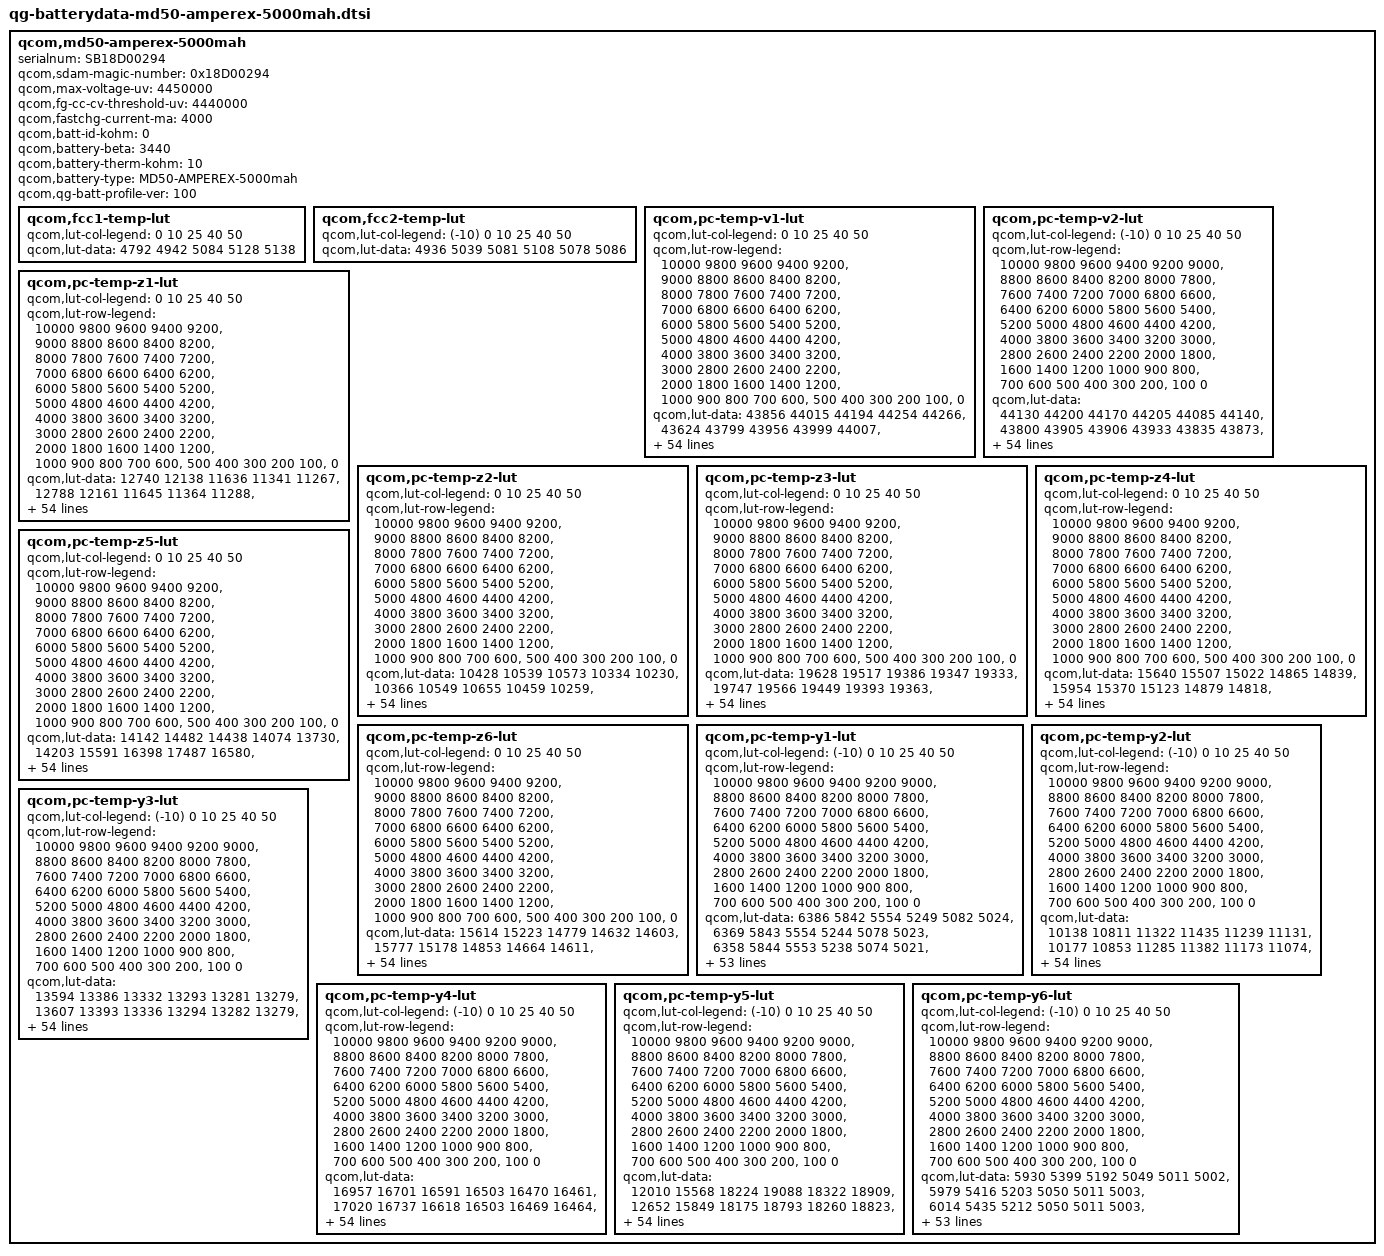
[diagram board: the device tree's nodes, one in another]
qcom,md50-amperex-5000mah {
    /* 4951798_Lenovo_Denver_5000mAH_PM7250B_averaged_MasterSlave_Dec1th2020 */
    serialnum = "SB18D00294";
    qcom,sdam-magic-number = <0x18D00294>;
    qcom,max-voltage-uv = <4450000>;
    qcom,fg-cc-cv-threshold-uv = <4440000>;
    qcom,fastchg-current-ma = <4000>;
    qcom,batt-id-kohm = <0>;
    qcom,battery-beta = <3440>;
    qcom,battery-therm-kohm = <10>;
    qcom,battery-type = "MD50-AMPEREX-5000mah";
    qcom,qg-batt-profile-ver = <100>;

	qcom,fcc1-temp-lut {
		qcom,lut-col-legend = <0 10 25 40 50>;
		qcom,lut-data = <4792 4942 5084 5128 5138>;
	};

	qcom,fcc2-temp-lut {
		qcom,lut-col-legend = <(-10) 0 10 25 40 50>;
		qcom,lut-data = <4936 5039 5081 5108 5078 5086>;
	};

	qcom,pc-temp-v1-lut {
		qcom,lut-col-legend = <0 10 25 40 50>;
		qcom,lut-row-legend = <10000 9800 9600 9400 9200>,
			<9000 8800 8600 8400 8200>,
			<8000 7800 7600 7400 7200>,
			<7000 6800 6600 6400 6200>,
			<6000 5800 5600 5400 5200>,
			<5000 4800 4600 4400 4200>,
			<4000 3800 3600 3400 3200>,
			<3000 2800 2600 2400 2200>,
			<2000 1800 1600 1400 1200>,
			<1000 900 800 700 600>,
			<500 400 300 200 100>,
			<0>;
		qcom,lut-data = <43856 44015 44194 44254 44266>,
			<43624 43799 43956 43999 44007>,
			<43397 43578 43741 43782 43786>,
			<43170 43352 43528 43574 43581>,
			<42935 43121 43301 43357 43368>,
			<42695 42884 43063 43127 43141>,
			<42459 42639 42824 42891 42908>,
			<42222 42398 42582 42652 42671>,
			<41990 42168 42338 42407 42430>,
			<41766 41944 42097 42165 42189>,
			<41548 41715 41857 41925 41950>,
			<41334 41479 41622 41687 41712>,
			<41123 41252 41393 41455 41480>,
			<40918 41040 41169 41226 41250>,
			<40714 40837 40952 41007 41028>,
			<40511 40638 40742 40796 40812>,
			<40318 40439 40542 40593 40604>,
			<40142 40250 40350 40396 40406>,
			<39977 40081 40167 40208 40216>,
			<39820 39922 40005 40034 40042>,
			<39676 39751 39845 39873 39884>,
			<39530 39563 39629 39678 39696>,
			<39363 39363 39322 39391 39416>,
			<39176 39133 39073 39122 39145>,
			<38999 38886 38935 38971 38992>,
			<38828 38733 38830 38862 38883>,
			<38676 38653 38734 38760 38781>,
			<38580 38591 38649 38663 38682>,
			<38517 38526 38570 38573 38587>,
			<38465 38464 38494 38487 38489>,
			<38417 38406 38425 38407 38395>,
			<38374 38351 38360 38331 38313>,
			<38335 38300 38301 38258 38242>,
			<38300 38254 38244 38191 38175>,
			<38268 38212 38191 38129 38107>,
			<38234 38171 38140 38070 38041>,
			<38202 38135 38091 38014 37975>,
			<38161 38095 38045 37961 37913>,
			<38101 38033 37983 37894 37837>,
			<38021 37940 37893 37798 37734>,
			<37926 37834 37786 37685 37616>,
			<37804 37715 37671 37573 37499>,
			<37664 37576 37540 37451 37372>,
			<37501 37407 37373 37291 37210>,
			<37350 37250 37218 37144 37068>,
			<37242 37150 37112 37049 36989>,
			<37197 37116 37078 37019 36957>,
			<37159 37095 37059 36998 36937>,
			<37128 37073 37036 36979 36915>,
			<37093 37032 36997 36932 36857>,
			<37022 36852 36798 36704 36606>,
			<36747 36412 36372 36271 36168>,
			<36244 35823 35797 35695 35590>,
			<35563 34994 35011 34912 34804>,
			<34404 33567 33789 33692 33577>,
			<30000 30000 30000 30000 30000>;
	};

	qcom,pc-temp-v2-lut {
		qcom,lut-col-legend = <(-10) 0 10 25 40 50>;
		qcom,lut-row-legend = <10000 9800 9600 9400 9200 9000>,
			<8800 8600 8400 8200 8000 7800>,
			<7600 7400 7200 7000 6800 6600>,
			<6400 6200 6000 5800 5600 5400>,
			<5200 5000 4800 4600 4400 4200>,
			<4000 3800 3600 3400 3200 3000>,
			<2800 2600 2400 2200 2000 1800>,
			<1600 1400 1200 1000 900 800>,
			<700 600 500 400 300 200>,
			<100 0>;
		qcom,lut-data = <44130 44200 44170 44205 44085 44140>,
			<43800 43905 43906 43933 43835 43873>,
			<43497 43631 43652 43674 43592 43618>,
			<43228 43380 43411 43433 43359 43381>,
			<42993 43154 43183 43210 43135 43160>,
			<42759 42925 42952 42981 42908 42935>,
			<42498 42680 42709 42741 42670 42699>,
			<42232 42430 42462 42497 42428 42458>,
			<41997 42182 42216 42253 42187 42217>,
			<41792 41935 41969 42008 41946 41975>,
			<41589 41695 41727 41767 41709 41738>,
			<41370 41463 41490 41528 41475 41503>,
			<41142 41240 41259 41296 41246 41273>,
			<40906 41036 41036 41071 41023 41048>,
			<40663 40849 40821 40851 40805 40829>,
			<40407 40644 40614 40640 40597 40619>,
			<40119 40400 40420 40433 40394 40417>,
			<39810 40142 40224 40234 40201 40223>,
			<39538 39892 40010 40052 40021 40041>,
			<39306 39644 39782 39874 39850 39867>,
			<39092 39412 39550 39669 39656 39675>,
			<38885 39197 39305 39425 39421 39455>,
			<38690 38999 39079 39192 39190 39237>,
			<38531 38821 38897 38991 38994 39034>,
			<38400 38661 38737 38811 38817 38843>,
			<38293 38510 38596 38665 38672 38692>,
			<38215 38360 38472 38543 38553 38571>,
			<38154 38227 38358 38435 38448 38464>,
			<38098 38125 38250 38334 38352 38363>,
			<38045 38040 38149 38241 38263 38269>,
			<37994 37978 38056 38156 38182 38186>,
			<37941 37933 37968 38077 38107 38110>,
			<37887 37894 37898 38006 38035 38037>,
			<37830 37848 37848 37943 37968 37970>,
			<37771 37801 37807 37882 37902 37901>,
			<37711 37751 37767 37816 37821 37810>,
			<37647 37700 37728 37746 37726 37696>,
			<37583 37644 37683 37672 37630 37587>,
			<37512 37578 37624 37594 37537 37492>,
			<37432 37500 37552 37512 37444 37401>,
			<37346 37411 37458 37426 37356 37310>,
			<37253 37302 37336 37330 37268 37217>,
			<37151 37177 37200 37207 37146 37100>,
			<37056 37032 37041 37068 37006 36963>,
			<36968 36873 36868 36935 36894 36839>,
			<36886 36755 36766 36882 36854 36801>,
			<36849 36715 36735 36865 36841 36790>,
			<36804 36681 36697 36844 36827 36776>,
			<36761 36645 36644 36815 36802 36748>,
			<36715 36592 36550 36745 36708 36645>,
			<36655 36493 36314 36489 36403 36324>,
			<36545 36197 35854 35990 35885 35813>,
			<36308 35588 35195 35337 35218 35144>,
			<35798 34615 34216 34436 34271 34212>,
			<34977 33356 32765 33077 33015 32896>,
			<34023 31708 27243 28003 28075 28051>;
	};

	qcom,pc-temp-z1-lut {
		qcom,lut-col-legend = <0 10 25 40 50>;
		qcom,lut-row-legend = <10000 9800 9600 9400 9200>,
			<9000 8800 8600 8400 8200>,
			<8000 7800 7600 7400 7200>,
			<7000 6800 6600 6400 6200>,
			<6000 5800 5600 5400 5200>,
			<5000 4800 4600 4400 4200>,
			<4000 3800 3600 3400 3200>,
			<3000 2800 2600 2400 2200>,
			<2000 1800 1600 1400 1200>,
			<1000 900 800 700 600>,
			<500 400 300 200 100>,
			<0>;
		qcom,lut-data = <12740 12138 11636 11341 11267>,
			<12788 12161 11645 11364 11288>,
			<12778 12168 11641 11362 11288>,
			<12768 12159 11636 11361 11289>,
			<12759 12139 11628 11359 11289>,
			<12739 12120 11615 11355 11288>,
			<12727 12099 11603 11351 11287>,
			<12713 12084 11593 11348 11287>,
			<12699 12078 11584 11347 11288>,
			<12686 12074 11576 11347 11290>,
			<12675 12066 11569 11349 11295>,
			<12661 12049 11567 11351 11299>,
			<12642 12036 11570 11351 11300>,
			<12620 12031 11572 11351 11300>,
			<12605 12028 11572 11351 11300>,
			<12590 12028 11571 11352 11301>,
			<12580 12028 11570 11353 11302>,
			<12576 12029 11572 11354 11304>,
			<12574 12027 11574 11355 11306>,
			<12573 12025 11576 11357 11307>,
			<12568 12025 11578 11359 11309>,
			<12563 12037 11579 11361 11311>,
			<12564 12049 11580 11361 11312>,
			<12569 12048 11580 11362 11313>,
			<12572 12044 11582 11363 11315>,
			<12568 12042 11586 11366 11317>,
			<12564 12045 11590 11369 11319>,
			<12569 12050 11595 11372 11322>,
			<12597 12058 11600 11376 11325>,
			<12620 12072 11605 11379 11329>,
			<12624 12077 11609 11383 11332>,
			<12622 12075 11614 11388 11336>,
			<12622 12073 11617 11392 11340>,
			<12624 12075 11622 11397 11343>,
			<12627 12083 11628 11402 11348>,
			<12630 12091 11635 11407 11353>,
			<12640 12099 11641 11412 11357>,
			<12651 12107 11647 11416 11361>,
			<12663 12121 11654 11420 11364>,
			<12678 12143 11661 11425 11367>,
			<12699 12156 11668 11429 11370>,
			<12734 12158 11677 11434 11374>,
			<12752 12161 11688 11439 11377>,
			<12758 12183 11700 11444 11380>,
			<12779 12197 11716 11451 11384>,
			<12813 12205 11726 11456 11387>,
			<12816 12195 11726 11457 11387>,
			<12789 12200 11726 11457 11387>,
			<12767 12199 11732 11459 11390>,
			<12770 12202 11731 11464 11394>,
			<12816 12213 11739 11470 11397>,
			<12807 12226 11759 11478 11404>,
			<12842 12245 11775 11488 11413>,
			<12897 12294 11789 11503 11427>,
			<12897 12294 11789 11503 11427>,
			<12897 12294 11789 11503 11427>;
	};

	qcom,pc-temp-z2-lut {
		qcom,lut-col-legend = <0 10 25 40 50>;
		qcom,lut-row-legend = <10000 9800 9600 9400 9200>,
			<9000 8800 8600 8400 8200>,
			<8000 7800 7600 7400 7200>,
			<7000 6800 6600 6400 6200>,
			<6000 5800 5600 5400 5200>,
			<5000 4800 4600 4400 4200>,
			<4000 3800 3600 3400 3200>,
			<3000 2800 2600 2400 2200>,
			<2000 1800 1600 1400 1200>,
			<1000 900 800 700 600>,
			<500 400 300 200 100>,
			<0>;
		qcom,lut-data = <10428 10539 10573 10334 10230>,
			<10366 10549 10655 10459 10259>,
			<10342 10545 10631 10553 10453>,
			<10323 10514 10591 10522 10435>,
			<10302 10464 10552 10487 10415>,
			<10285 10427 10507 10442 10394>,
			<10273 10394 10470 10401 10370>,
			<10264 10375 10441 10378 10333>,
			<10258 10407 10418 10361 10287>,
			<10269 10467 10397 10341 10274>,
			<10309 10473 10380 10313 10277>,
			<10329 10414 10375 10298 10281>,
			<10304 10372 10386 10317 10283>,
			<10272 10384 10401 10349 10285>,
			<10270 10409 10418 10352 10291>,
			<10278 10437 10438 10342 10310>,
			<10291 10473 10461 10337 10327>,
			<10315 10507 10491 10348 10333>,
			<10353 10533 10515 10367 10337>,
			<10391 10555 10525 10378 10326>,
			<10429 10573 10534 10385 10279>,
			<10463 10587 10570 10406 10263>,
			<10486 10599 10700 10577 10473>,
			<10503 10612 10781 10744 10706>,
			<10516 10624 10697 10640 10634>,
			<10527 10626 10574 10372 10396>,
			<10536 10614 10558 10293 10315>,
			<10543 10602 10576 10329 10337>,
			<10547 10605 10597 10372 10377>,
			<10551 10620 10626 10405 10506>,
			<10558 10633 10652 10443 10701>,
			<10566 10646 10660 10476 10731>,
			<10575 10655 10664 10541 10623>,
			<10586 10656 10665 10577 10498>,
			<10597 10656 10664 10555 10379>,
			<10607 10656 10663 10526 10281>,
			<10617 10661 10665 10525 10273>,
			<10629 10670 10669 10540 10299>,
			<10646 10685 10678 10565 10334>,
			<10668 10710 10717 10642 10393>,
			<10694 10733 10757 10714 10458>,
			<10724 10748 10771 10705 10497>,
			<10770 10768 10780 10671 10531>,
			<10855 10816 10790 10663 10597>,
			<11173 11075 10863 10645 10585>,
			<10956 11260 10953 10559 10451>,
			<10881 11255 10928 10553 10429>,
			<10872 11442 10907 10553 10460>,
			<10766 11821 10906 10568 10475>,
			<10663 11979 10974 10653 10540>,
			<10630 11837 11025 10606 10480>,
			<10549 11596 10970 10403 10240>,
			<10360 11358 10868 10315 10161>,
			<10190 10935 10774 10279 10120>,
			<10190 10935 10774 10279 10120>,
			<10190 10935 10774 10279 10120>;
	};

	qcom,pc-temp-z3-lut {
		qcom,lut-col-legend = <0 10 25 40 50>;
		qcom,lut-row-legend = <10000 9800 9600 9400 9200>,
			<9000 8800 8600 8400 8200>,
			<8000 7800 7600 7400 7200>,
			<7000 6800 6600 6400 6200>,
			<6000 5800 5600 5400 5200>,
			<5000 4800 4600 4400 4200>,
			<4000 3800 3600 3400 3200>,
			<3000 2800 2600 2400 2200>,
			<2000 1800 1600 1400 1200>,
			<1000 900 800 700 600>,
			<500 400 300 200 100>,
			<0>;
		qcom,lut-data = <19628 19517 19386 19347 19333>,
			<19747 19566 19449 19393 19363>,
			<19786 19594 19460 19413 19395>,
			<19802 19604 19466 19418 19399>,
			<19806 19610 19475 19422 19404>,
			<19809 19611 19485 19429 19413>,
			<19809 19610 19488 19433 19419>,
			<19806 19610 19484 19434 19420>,
			<19802 19616 19479 19435 19419>,
			<19799 19624 19476 19435 19418>,
			<19796 19620 19473 19432 19414>,
			<19793 19594 19469 19428 19411>,
			<19781 19571 19461 19424 19407>,
			<19765 19563 19454 19419 19404>,
			<19758 19557 19449 19413 19401>,
			<19755 19550 19445 19406 19397>,
			<19752 19539 19442 19399 19393>,
			<19739 19531 19438 19395 19389>,
			<19718 19529 19433 19391 19384>,
			<19705 19528 19425 19386 19377>,
			<19699 19529 19417 19379 19367>,
			<19695 19535 19419 19377 19363>,
			<19697 19543 19441 19387 19370>,
			<19707 19549 19455 19398 19378>,
			<19712 19554 19443 19389 19371>,
			<19712 19555 19424 19367 19349>,
			<19711 19546 19417 19357 19339>,
			<19709 19536 19413 19355 19337>,
			<19702 19531 19412 19354 19337>,
			<19693 19528 19415 19356 19352>,
			<19687 19527 19419 19361 19383>,
			<19682 19530 19424 19369 19390>,
			<19676 19532 19429 19384 19387>,
			<19670 19533 19433 19393 19384>,
			<19665 19533 19434 19392 19378>,
			<19660 19533 19435 19390 19371>,
			<19656 19530 19433 19386 19365>,
			<19652 19525 19426 19378 19359>,
			<19647 19522 19421 19374 19356>,
			<19641 19518 19419 19374 19354>,
			<19632 19513 19417 19374 19353>,
			<19619 19506 19412 19372 19355>,
			<19602 19497 19406 19369 19360>,
			<19580 19486 19402 19369 19367>,
			<19435 19451 19391 19366 19367>,
			<19315 19416 19376 19353 19346>,
			<19307 19412 19376 19347 19341>,
			<19304 19360 19369 19345 19333>,
			<19295 19299 19369 19337 19328>,
			<19294 19291 19356 19330 19324>,
			<19293 19295 19358 19341 19338>,
			<19297 19300 19358 19365 19362>,
			<19301 19301 19354 19367 19364>,
			<19323 19331 19348 19360 19359>,
			<19323 19331 19348 19360 19359>,
			<19323 19331 19348 19360 19359>;
	};

	qcom,pc-temp-z4-lut {
		qcom,lut-col-legend = <0 10 25 40 50>;
		qcom,lut-row-legend = <10000 9800 9600 9400 9200>,
			<9000 8800 8600 8400 8200>,
			<8000 7800 7600 7400 7200>,
			<7000 6800 6600 6400 6200>,
			<6000 5800 5600 5400 5200>,
			<5000 4800 4600 4400 4200>,
			<4000 3800 3600 3400 3200>,
			<3000 2800 2600 2400 2200>,
			<2000 1800 1600 1400 1200>,
			<1000 900 800 700 600>,
			<500 400 300 200 100>,
			<0>;
		qcom,lut-data = <15640 15507 15022 14865 14839>,
			<15954 15370 15123 14879 14818>,
			<15744 15252 15065 14906 14861>,
			<15522 15150 14978 14866 14835>,
			<15389 15063 14922 14833 14810>,
			<15277 14996 14878 14808 14789>,
			<15187 14945 14843 14786 14770>,
			<15113 14899 14817 14767 14754>,
			<15050 14842 14795 14749 14741>,
			<14990 14788 14775 14734 14727>,
			<14934 14772 14757 14719 14713>,
			<14897 14780 14742 14708 14701>,
			<14877 14785 14729 14700 14696>,
			<14862 14772 14719 14694 14692>,
			<14846 14755 14712 14691 14688>,
			<14827 14747 14706 14688 14685>,
			<14813 14744 14701 14686 14681>,
			<14806 14741 14696 14681 14678>,
			<14801 14731 14693 14677 14676>,
			<14792 14716 14691 14674 14673>,
			<14767 14712 14690 14672 14670>,
			<14745 14716 14697 14673 14671>,
			<14745 14725 14745 14718 14715>,
			<14754 14753 14787 14771 14771>,
			<14766 14804 14805 14792 14789>,
			<14791 14822 14817 14806 14800>,
			<14819 14817 14817 14808 14803>,
			<14825 14810 14809 14801 14795>,
			<14820 14801 14798 14789 14782>,
			<14813 14791 14785 14776 14754>,
			<14805 14779 14770 14759 14714>,
			<14795 14766 14754 14739 14693>,
			<14785 14753 14736 14712 14683>,
			<14774 14743 14722 14694 14677>,
			<14764 14734 14711 14685 14674>,
			<14753 14726 14703 14680 14673>,
			<14742 14719 14701 14679 14672>,
			<14733 14714 14700 14678 14671>,
			<14724 14712 14700 14678 14671>,
			<14716 14712 14705 14686 14682>,
			<14711 14711 14709 14695 14694>,
			<14707 14704 14707 14695 14691>,
			<14701 14696 14701 14691 14681>,
			<14689 14689 14696 14689 14679>,
			<14753 14670 14682 14680 14672>,
			<14856 14667 14662 14665 14661>,
			<14863 14666 14657 14664 14661>,
			<14863 14717 14650 14656 14656>,
			<14867 14779 14636 14644 14640>,
			<14865 14781 14643 14638 14631>,
			<14859 14781 14655 14654 14651>,
			<14860 14789 14671 14651 14651>,
			<14877 14795 14679 14655 14655>,
			<14876 14775 14689 14666 14663>,
			<14876 14775 14689 14666 14663>,
			<14876 14775 14689 14666 14663>;
	};

	qcom,pc-temp-z5-lut {
		qcom,lut-col-legend = <0 10 25 40 50>;
		qcom,lut-row-legend = <10000 9800 9600 9400 9200>,
			<9000 8800 8600 8400 8200>,
			<8000 7800 7600 7400 7200>,
			<7000 6800 6600 6400 6200>,
			<6000 5800 5600 5400 5200>,
			<5000 4800 4600 4400 4200>,
			<4000 3800 3600 3400 3200>,
			<3000 2800 2600 2400 2200>,
			<2000 1800 1600 1400 1200>,
			<1000 900 800 700 600>,
			<500 400 300 200 100>,
			<0>;
		qcom,lut-data = <14142 14482 14438 14074 13730>,
			<14203 15591 16398 17487 16580>,
			<14677 16416 16880 18337 19043>,
			<15195 16914 17289 18778 19541>,
			<15595 17313 17988 19329 20189>,
			<15992 17842 18934 20100 21526>,
			<16448 18519 19527 20931 22885>,
			<16998 19208 19762 21723 23631>,
			<17622 20065 19983 22520 24156>,
			<18330 20952 20431 23352 24885>,
			<19139 21255 21107 24237 26051>,
			<19912 21270 21788 25153 27250>,
			<20538 21388 22508 26334 28188>,
			<21192 22055 23293 27402 29049>,
			<22312 23124 24143 27480 29966>,
			<24428 23849 25071 27043 31021>,
			<25824 24265 26082 26808 32071>,
			<25632 24776 27403 27789 33357>,
			<25184 25829 28168 29056 34447>,
			<25160 27704 27921 29261 34010>,
			<27598 30682 27475 29278 31797>,
			<32007 37675 30444 29670 30838>,
			<39676 44278 48133 36586 34522>,
			<53017 46972 59546 43491 38576>,
			<59794 48773 48851 38538 34762>,
			<59547 48844 31968 25367 23362>,
			<58949 42032 26419 19929 18234>,
			<57523 34374 24057 18570 17023>,
			<52378 32068 23274 18011 16500>,
			<47310 30756 23490 18140 18989>,
			<44987 30436 23987 18552 24397>,
			<43313 31810 25044 19705 27123>,
			<42202 34038 27467 23751 28515>,
			<41307 36302 30347 27845 29266>,
			<40748 38982 34686 31221 29600>,
			<40849 40742 38088 33747 29822>,
			<41561 41758 38279 33841 29919>,
			<42531 42373 38149 33103 30051>,
			<44569 42424 37911 32761 30100>,
			<46946 42369 37090 32990 29657>,
			<46920 42232 35718 33239 28909>,
			<43256 39589 32660 30866 28053>,
			<41591 36883 29293 25971 27204>,
			<41383 35898 29387 27012 30897>,
			<27291 36795 30120 27861 33429>,
			<13418 29466 30007 25135 24159>,
			<13080 27846 30372 22553 21460>,
			<12951 19629 28007 22984 20085>,
			<12646 13094 31452 23001 21815>,
			<12597 12869 25755 22617 23443>,
			<12643 13066 23585 23372 25064>,
			<12749 13047 19601 24762 25585>,
			<12575 12882 17795 22685 23029>,
			<13336 14055 16375 18289 18472>,
			<13336 14055 16375 18289 18472>,
			<13336 14055 16375 18289 18472>;
	};

	qcom,pc-temp-z6-lut {
		qcom,lut-col-legend = <0 10 25 40 50>;
		qcom,lut-row-legend = <10000 9800 9600 9400 9200>,
			<9000 8800 8600 8400 8200>,
			<8000 7800 7600 7400 7200>,
			<7000 6800 6600 6400 6200>,
			<6000 5800 5600 5400 5200>,
			<5000 4800 4600 4400 4200>,
			<4000 3800 3600 3400 3200>,
			<3000 2800 2600 2400 2200>,
			<2000 1800 1600 1400 1200>,
			<1000 900 800 700 600>,
			<500 400 300 200 100>,
			<0>;
		qcom,lut-data = <15614 15223 14779 14632 14603>,
			<15777 15178 14853 14664 14611>,
			<15683 15132 14831 14685 14645>,
			<15579 15085 14796 14672 14638>,
			<15508 15039 14775 14661 14631>,
			<15444 15003 14758 14653 14627>,
			<15390 14973 14743 14646 14622>,
			<15344 14946 14728 14639 14617>,
			<15304 14920 14714 14632 14612>,
			<15268 14896 14702 14625 14606>,
			<15237 14879 14692 14618 14599>,
			<15210 14866 14683 14612 14593>,
			<15188 14855 14673 14606 14588>,
			<15168 14843 14665 14600 14585>,
			<15152 14831 14659 14595 14581>,
			<15138 14822 14654 14590 14577>,
			<15124 14814 14649 14585 14573>,
			<15109 14808 14645 14581 14569>,
			<15094 14801 14641 14577 14565>,
			<15079 14796 14636 14572 14560>,
			<15063 14795 14632 14567 14554>,
			<15051 14800 14637 14567 14552>,
			<15053 14809 14671 14594 14577>,
			<15062 14826 14693 14622 14604>,
			<15073 14852 14693 14622 14605>,
			<15086 14860 14691 14619 14601>,
			<15098 14855 14689 14616 14596>,
			<15099 14848 14684 14612 14592>,
			<15095 14842 14680 14608 14588>,
			<15089 14837 14676 14604 14585>,
			<15084 14833 14673 14600 14584>,
			<15078 14830 14669 14596 14581>,
			<15072 14827 14666 14593 14576>,
			<15066 14824 14663 14590 14571>,
			<15061 14822 14660 14588 14567>,
			<15057 14820 14658 14585 14564>,
			<15054 14817 14655 14582 14560>,
			<15052 14815 14653 14578 14557>,
			<15054 14816 14652 14576 14556>,
			<15056 14818 14654 14580 14559>,
			<15058 14819 14656 14584 14563>,
			<15060 14818 14655 14583 14563>,
			<15060 14815 14651 14580 14562>,
			<15057 14812 14650 14580 14565>,
			<15024 14795 14642 14576 14563>,
			<15014 14780 14628 14563 14547>,
			<15013 14777 14626 14560 14545>,
			<15012 14773 14620 14555 14539>,
			<15011 14770 14615 14546 14529>,
			<15012 14770 14612 14540 14523>,
			<15016 14777 14621 14554 14539>,
			<15027 14788 14631 14568 14555>,
			<15047 14799 14637 14573 14561>,
			<15073 14819 14643 14578 14565>,
			<15073 14819 14643 14578 14565>,
			<15073 14819 14643 14578 14565>;
	};

	qcom,pc-temp-y1-lut {
		qcom,lut-col-legend = <(-10) 0 10 25 40 50>;
		qcom,lut-row-legend = <10000 9800 9600 9400 9200 9000>,
			<8800 8600 8400 8200 8000 7800>,
			<7600 7400 7200 7000 6800 6600>,
			<6400 6200 6000 5800 5600 5400>,
			<5200 5000 4800 4600 4400 4200>,
			<4000 3800 3600 3400 3200 3000>,
			<2800 2600 2400 2200 2000 1800>,
			<1600 1400 1200 1000 900 800>,
			<700 600 500 400 300 200>,
			<100 0>;
		qcom,lut-data = <6386 5842 5554 5249 5082 5024>,
			<6369 5843 5554 5244 5078 5023>,
			<6358 5844 5553 5238 5074 5021>,
			<6352 5846 5550 5233 5070 5020>,
			<6349 5847 5548 5229 5067 5019>,
			<6349 5848 5547 5224 5064 5017>,
			<6352 5849 5544 5221 5062 5016>,
			<6359 5849 5542 5217 5061 5015>,
			<6362 5849 5541 5214 5059 5014>,
			<6360 5847 5539 5210 5058 5014>,
			<6358 5846 5537 5207 5056 5014>,
			<6358 5848 5533 5204 5055 5013>,
			<6357 5850 5530 5202 5054 5013>,
			<6359 5852 5529 5202 5054 5013>,
			<6365 5855 5530 5202 5054 5013>,
			<6370 5857 5530 5202 5054 5013>,
			<6372 5858 5530 5203 5055 5014>,
			<6373 5859 5530 5203 5055 5015>,
			<6373 5860 5530 5204 5056 5015>,
			<6369 5861 5531 5205 5057 5016>,
			<6365 5862 5532 5206 5058 5017>,
			<6364 5863 5535 5208 5058 5018>,
			<6363 5864 5538 5211 5059 5019>,
			<6362 5867 5540 5214 5061 5020>,
			<6361 5870 5542 5217 5063 5021>,
			<6359 5873 5544 5221 5065 5023>,
			<6357 5874 5545 5224 5067 5025>,
			<6355 5875 5547 5228 5070 5027>,
			<6354 5876 5549 5232 5072 5029>,
			<6355 5876 5552 5237 5074 5031>,
			<6358 5877 5554 5241 5077 5033>,
			<6358 5877 5556 5245 5080 5035>,
			<6357 5878 5558 5249 5083 5037>,
			<6356 5879 5562 5253 5086 5039>,
			<6363 5880 5566 5257 5089 5042>,
			<6372 5880 5568 5261 5091 5043>,
			<6370 5880 5570 5264 5093 5045>,
			<6356 5880 5572 5267 5095 5047>,
			<6347 5881 5577 5268 5096 5048>,
			<6348 5882 5583 5269 5098 5050>,
			<6351 5884 5586 5272 5099 5051>,
			<6355 5886 5588 5276 5100 5052>,
			<6362 5888 5592 5281 5102 5054>,
			<6363 5891 5597 5287 5105 5056>,
			<6364 5902 5600 5294 5109 5058>,
			<6374 5924 5611 5300 5112 5061>,
			<6410 5926 5610 5304 5113 5060>,
			<6437 5931 5613 5306 5112 5061>,
			<6424 5938 5613 5309 5112 5061>,
			<6447 5948 5616 5310 5113 5062>,
			<6454 5974 5630 5311 5115 5064>,
			<6546 6012 5657 5324 5120 5068>,
			<6674 6156 5714 5345 5128 5076>,
			<6958 6471 5836 5372 5139 5085>,
			<6958 6471 5836 5372 5139 5085>,
			<6958 6471 5836 5372 5139 5085>;
	};

	qcom,pc-temp-y2-lut {
		qcom,lut-col-legend = <(-10) 0 10 25 40 50>;
		qcom,lut-row-legend = <10000 9800 9600 9400 9200 9000>,
			<8800 8600 8400 8200 8000 7800>,
			<7600 7400 7200 7000 6800 6600>,
			<6400 6200 6000 5800 5600 5400>,
			<5200 5000 4800 4600 4400 4200>,
			<4000 3800 3600 3400 3200 3000>,
			<2800 2600 2400 2200 2000 1800>,
			<1600 1400 1200 1000 900 800>,
			<700 600 500 400 300 200>,
			<100 0>;
		qcom,lut-data = <10138 10811 11322 11435 11239 11131>,
			<10177 10853 11285 11382 11173 11074>,
			<10255 10883 11249 11330 11093 11011>,
			<10346 10902 11214 11282 11012 10950>,
			<10423 10912 11180 11239 10945 10899>,
			<10458 10915 11146 11200 10908 10866>,
			<10458 10903 11110 11163 10894 10844>,
			<10456 10887 11078 11133 10883 10830>,
			<10483 10887 11055 11119 10867 10826>,
			<10677 10901 11036 11108 10846 10828>,
			<10833 10918 11030 11105 10838 10824>,
			<10798 10934 11038 11101 10852 10799>,
			<10721 10956 11054 11098 10870 10776>,
			<10706 11001 11083 11100 10878 10776>,
			<10782 11091 11135 11109 10889 10783>,
			<10860 11163 11192 11123 10897 10793>,
			<10749 11212 11258 11167 10926 10823>,
			<10448 11243 11316 11228 10969 10864>,
			<10313 11241 11352 11311 11037 10906>,
			<10012 11221 11380 11403 11151 10957>,
			<9713 11212 11386 11431 11230 11017>,
			<9686 11220 11378 11438 11285 11106>,
			<9682 11232 11372 11440 11314 11163>,
			<9679 11245 11391 11436 11264 11134>,
			<9675 11261 11433 11429 11161 11077>,
			<9672 11266 11460 11431 11136 11065>,
			<9670 11236 11476 11453 11168 11082>,
			<9669 11204 11487 11483 11215 11102>,
			<9667 11206 11493 11527 11286 11142>,
			<9666 11218 11497 11576 11373 11197>,
			<9665 11221 11497 11611 11411 11224>,
			<9664 11157 11491 11638 11424 11243>,
			<9663 11032 11482 11658 11440 11271>,
			<9662 10670 11466 11674 11487 11379>,
			<9662 10009 11442 11685 11539 11503>,
			<9661 9747 11408 11671 11530 11500>,
			<9661 9711 11353 11626 11452 11423>,
			<9661 9692 11289 11586 11390 11353>,
			<9660 9681 11218 11552 11352 11278>,
			<9660 9674 11131 11523 11322 11211>,
			<9660 9669 11015 11504 11334 11201>,
			<9660 9666 10862 11488 11373 11217>,
			<9660 9663 10731 11466 11345 11225>,
			<9659 9661 10482 11436 11259 11197>,
			<9659 9660 9883 11408 11162 11031>,
			<9658 9659 9757 11316 11045 10899>,
			<9657 9658 9709 11293 11066 10894>,
			<9657 9657 9685 11266 11088 10910>,
			<9656 9656 9673 11245 11120 10956>,
			<9654 9655 9666 11265 11120 10926>,
			<9651 9654 9660 11191 11029 10846>,
			<9650 9650 9656 11091 10932 10782>,
			<9648 9649 9652 10951 10884 10698>,
			<9648 9648 9653 10809 10735 10546>,
			<9648 9648 9653 10809 10735 10546>,
			<9648 9648 9653 10809 10735 10546>;
	};

	qcom,pc-temp-y3-lut {
		qcom,lut-col-legend = <(-10) 0 10 25 40 50>;
		qcom,lut-row-legend = <10000 9800 9600 9400 9200 9000>,
			<8800 8600 8400 8200 8000 7800>,
			<7600 7400 7200 7000 6800 6600>,
			<6400 6200 6000 5800 5600 5400>,
			<5200 5000 4800 4600 4400 4200>,
			<4000 3800 3600 3400 3200 3000>,
			<2800 2600 2400 2200 2000 1800>,
			<1600 1400 1200 1000 900 800>,
			<700 600 500 400 300 200>,
			<100 0>;
		qcom,lut-data = <13594 13386 13332 13293 13281 13279>,
			<13607 13393 13336 13294 13282 13279>,
			<13615 13401 13339 13295 13283 13280>,
			<13619 13410 13343 13296 13284 13281>,
			<13621 13417 13346 13298 13284 13282>,
			<13621 13422 13349 13299 13285 13282>,
			<13613 13423 13351 13299 13285 13284>,
			<13599 13425 13353 13300 13286 13285>,
			<13598 13425 13354 13300 13287 13285>,
			<13611 13425 13355 13301 13287 13285>,
			<13623 13425 13356 13301 13288 13286>,
			<13585 13431 13356 13301 13289 13286>,
			<13509 13440 13356 13301 13289 13287>,
			<13487 13434 13355 13303 13290 13287>,
			<13500 13403 13350 13307 13291 13287>,
			<13511 13387 13348 13309 13292 13287>,
			<13500 13394 13347 13309 13294 13289>,
			<13473 13404 13346 13309 13296 13292>,
			<13464 13401 13344 13308 13297 13293>,
			<13466 13386 13341 13307 13299 13294>,
			<13468 13374 13337 13305 13300 13294>,
			<13467 13368 13331 13303 13295 13292>,
			<13464 13363 13326 13300 13290 13288>,
			<13460 13358 13323 13297 13286 13285>,
			<13456 13353 13321 13293 13283 13281>,
			<13452 13350 13320 13292 13281 13280>,
			<13460 13348 13319 13291 13281 13280>,
			<13490 13346 13318 13291 13281 13280>,
			<13525 13340 13317 13291 13282 13280>,
			<13562 13327 13314 13291 13282 13278>,
			<13603 13323 13313 13291 13282 13278>,
			<13647 13327 13312 13291 13281 13278>,
			<13694 13333 13311 13291 13281 13279>,
			<13744 13340 13312 13292 13282 13280>,
			<13798 13349 13313 13292 13283 13282>,
			<13854 13362 13314 13292 13283 13282>,
			<13910 13380 13318 13292 13282 13281>,
			<13965 13405 13321 13291 13281 13280>,
			<14017 13436 13325 13290 13281 13280>,
			<14063 13477 13328 13290 13280 13281>,
			<14106 13527 13332 13290 13281 13282>,
			<14145 13593 13335 13291 13285 13283>,
			<14182 13675 13340 13292 13284 13283>,
			<14228 13778 13347 13292 13281 13282>,
			<14291 13900 13351 13289 13280 13278>,
			<14385 13983 13375 13296 13286 13284>,
			<14416 14094 13410 13299 13289 13288>,
			<14515 14220 13453 13303 13293 13290>,
			<14698 14356 13520 13310 13296 13292>,
			<15015 14540 13639 13314 13295 13290>,
			<16087 14958 13847 13311 13290 13287>,
			<19329 17084 14250 13312 13290 13287>,
			<29072 26276 15249 13322 13295 13291>,
			<61994 65535 21487 13340 13302 13300>,
			<61994 65535 21487 13340 13302 13300>,
			<61994 65535 21487 13340 13302 13300>;
	};

	qcom,pc-temp-y4-lut {
		qcom,lut-col-legend = <(-10) 0 10 25 40 50>;
		qcom,lut-row-legend = <10000 9800 9600 9400 9200 9000>,
			<8800 8600 8400 8200 8000 7800>,
			<7600 7400 7200 7000 6800 6600>,
			<6400 6200 6000 5800 5600 5400>,
			<5200 5000 4800 4600 4400 4200>,
			<4000 3800 3600 3400 3200 3000>,
			<2800 2600 2400 2200 2000 1800>,
			<1600 1400 1200 1000 900 800>,
			<700 600 500 400 300 200>,
			<100 0>;
		qcom,lut-data = <16957 16701 16591 16503 16470 16461>,
			<17020 16737 16618 16503 16469 16464>,
			<17129 16801 16649 16503 16469 16465>,
			<17250 16872 16678 16503 16469 16466>,
			<17350 16929 16699 16503 16469 16466>,
			<17394 16952 16706 16503 16470 16466>,
			<17391 16949 16701 16504 16470 16466>,
			<17382 16944 16693 16504 16472 16465>,
			<17368 16943 16688 16506 16473 16465>,
			<17335 16944 16684 16510 16475 16467>,
			<17311 16944 16682 16515 16478 16469>,
			<17376 16941 16687 16522 16482 16471>,
			<17509 16938 16697 16529 16487 16474>,
			<17540 16969 16715 16534 16491 16477>,
			<17428 17090 16747 16538 16496 16482>,
			<17287 17150 16779 16546 16500 16487>,
			<17188 17080 16812 16561 16506 16490>,
			<17099 16973 16834 16582 16514 16495>,
			<17035 16908 16824 16616 16531 16506>,
			<16994 16859 16787 16655 16556 16522>,
			<16955 16815 16744 16657 16562 16527>,
			<16895 16773 16680 16612 16548 16526>,
			<16821 16737 16624 16563 16527 16525>,
			<16791 16707 16598 16526 16503 16507>,
			<16786 16683 16579 16497 16478 16475>,
			<16784 16653 16570 16493 16472 16467>,
			<16784 16602 16565 16493 16473 16467>,
			<16786 16562 16560 16495 16475 16468>,
			<16787 16562 16554 16499 16479 16472>,
			<16789 16574 16548 16505 16486 16480>,
			<16793 16585 16538 16510 16494 16487>,
			<16797 16595 16521 16516 16505 16495>,
			<16804 16607 16512 16522 16514 16503>,
			<16812 16633 16517 16528 16519 16511>,
			<16819 16673 16529 16532 16523 16517>,
			<16825 16703 16544 16528 16520 16513>,
			<16830 16723 16565 16517 16505 16494>,
			<16835 16737 16586 16506 16492 16483>,
			<16838 16747 16608 16497 16483 16481>,
			<16835 16753 16627 16491 16478 16480>,
			<16828 16754 16637 16495 16480 16484>,
			<16822 16748 16642 16502 16486 16492>,
			<16814 16739 16645 16505 16483 16489>,
			<16814 16729 16649 16504 16469 16474>,
			<16821 16720 16653 16483 16456 16448>,
			<16834 16705 16661 16494 16467 16466>,
			<16813 16717 16685 16511 16489 16498>,
			<16823 16735 16716 16533 16525 16539>,
			<16834 16762 16762 16570 16566 16579>,
			<16853 16802 16826 16608 16567 16572>,
			<16955 16843 16875 16581 16504 16498>,
			<17448 17110 16919 16556 16481 16480>,
			<19570 20596 17091 16592 16486 16481>,
			<38612 65535 21689 16651 16511 16500>,
			<38612 65535 21689 16651 16511 16500>,
			<38612 65535 21689 16651 16511 16500>;
	};

	qcom,pc-temp-y5-lut {
		qcom,lut-col-legend = <(-10) 0 10 25 40 50>;
		qcom,lut-row-legend = <10000 9800 9600 9400 9200 9000>,
			<8800 8600 8400 8200 8000 7800>,
			<7600 7400 7200 7000 6800 6600>,
			<6400 6200 6000 5800 5600 5400>,
			<5200 5000 4800 4600 4400 4200>,
			<4000 3800 3600 3400 3200 3000>,
			<2800 2600 2400 2200 2000 1800>,
			<1600 1400 1200 1000 900 800>,
			<700 600 500 400 300 200>,
			<100 0>;
		qcom,lut-data = <12010 15568 18224 19088 18322 18909>,
			<12652 15849 18175 18793 18260 18823>,
			<13688 16238 18187 18473 18090 18747>,
			<14832 16646 18232 18136 17846 18683>,
			<15799 16984 18279 17793 17560 18634>,
			<16300 17164 18298 17453 17262 18604>,
			<16381 17241 18325 17120 16896 18608>,
			<16427 17286 18355 16763 16506 18608>,
			<16785 17206 18253 16323 16215 18369>,
			<18782 16873 17839 15792 15981 17633>,
			<20349 16694 17372 15303 15725 17190>,
			<19312 17132 16903 14773 15377 16825>,
			<17136 17709 16375 14419 15060 16410>,
			<16803 17565 15685 14573 14951 15995>,
			<20086 16722 14865 14996 15024 15345>,
			<23009 16337 14647 15105 15071 15144>,
			<21852 18895 15789 14790 15037 15546>,
			<18761 22031 17482 14522 15034 15949>,
			<17199 22138 19151 14705 15144 15866>,
			<16523 21313 20897 15289 15355 15587>,
			<15930 20930 21479 16502 15873 15742>,
			<15446 21103 21559 19919 18191 17712>,
			<14883 21338 21611 22099 20086 19306>,
			<14199 21470 21657 21370 19727 19281>,
			<13076 21642 21702 20106 18739 19133>,
			<12157 21858 21844 19568 18019 18915>,
			<12080 22253 22390 19196 17375 18479>,
			<12159 22576 22771 19046 17031 17898>,
			<12239 20910 22701 19018 17071 16840>,
			<12425 16198 22514 19002 17146 15696>,
			<12654 14376 22267 19134 17105 15527>,
			<12760 14777 21864 19551 16768 15680>,
			<12828 15177 21361 20144 16548 15948>,
			<12893 14821 20574 21373 17408 17090>,
			<12958 13861 19768 22493 18833 18596>,
			<13027 13532 19456 22743 19480 19173>,
			<13139 13716 19258 22865 19894 19435>,
			<13325 13941 19115 22801 20050 19767>,
			<13452 14108 18967 21618 19459 20443>,
			<13536 14291 18759 20230 18689 21082>,
			<13601 14332 18413 19470 19237 21242>,
			<13498 14219 17908 18952 21085 21313>,
			<13081 14096 17674 18715 20738 23236>,
			<12726 13964 17182 18612 19652 24198>,
			<12459 13287 14389 18777 18120 17690>,
			<12340 13092 13841 18881 17529 17967>,
			<12523 13122 13935 18271 17446 17025>,
			<12421 13304 13891 17856 17260 16123>,
			<12609 13347 13828 18161 17050 15722>,
			<12756 13249 13849 18393 16451 14986>,
			<12272 13259 13592 18294 16921 16256>,
			<10925 11687 13199 19245 17494 16415>,
			<9605 9516 12194 18959 18614 16705>,
			<8931 8859 9787 19350 22432 22857>,
			<8931 8859 9787 19350 22432 22857>,
			<8931 8859 9787 19350 22432 22857>;
	};

	qcom,pc-temp-y6-lut {
		qcom,lut-col-legend = <(-10) 0 10 25 40 50>;
		qcom,lut-row-legend = <10000 9800 9600 9400 9200 9000>,
			<8800 8600 8400 8200 8000 7800>,
			<7600 7400 7200 7000 6800 6600>,
			<6400 6200 6000 5800 5600 5400>,
			<5200 5000 4800 4600 4400 4200>,
			<4000 3800 3600 3400 3200 3000>,
			<2800 2600 2400 2200 2000 1800>,
			<1600 1400 1200 1000 900 800>,
			<700 600 500 400 300 200>,
			<100 0>;
		qcom,lut-data = <5930 5399 5192 5049 5011 5002>,
			<5979 5416 5203 5050 5011 5003>,
			<6014 5435 5212 5050 5011 5003>,
			<6037 5452 5218 5050 5012 5004>,
			<6049 5465 5222 5050 5012 5005>,
			<6052 5469 5223 5051 5013 5006>,
			<6041 5467 5221 5051 5013 5006>,
			<6022 5462 5217 5051 5014 5007>,
			<6016 5458 5214 5051 5015 5007>,
			<6015 5454 5211 5052 5016 5008>,
			<6015 5453 5210 5053 5017 5009>,
			<6011 5454 5210 5055 5018 5010>,
			<6003 5456 5211 5057 5020 5011>,
			<5992 5461 5213 5059 5022 5013>,
			<5977 5474 5218 5063 5024 5014>,
			<5956 5480 5224 5067 5027 5016>,
			<5923 5468 5233 5072 5029 5018>,
			<5879 5446 5239 5077 5033 5021>,
			<5851 5426 5235 5086 5039 5025>,
			<5835 5404 5222 5096 5047 5030>,
			<5823 5386 5207 5096 5049 5032>,
			<5812 5373 5185 5081 5041 5030>,
			<5802 5363 5166 5065 5031 5026>,
			<5799 5357 5158 5052 5021 5017>,
			<5806 5353 5152 5042 5012 5006>,
			<5819 5348 5151 5040 5010 5004>,
			<5837 5342 5151 5040 5010 5004>,
			<5867 5337 5151 5041 5011 5004>,
			<5901 5338 5151 5043 5012 5005>,
			<5936 5346 5150 5045 5015 5006>,
			<5974 5357 5149 5047 5017 5008>,
			<6015 5377 5147 5050 5020 5011>,
			<6058 5405 5146 5052 5022 5014>,
			<6102 5434 5150 5055 5025 5018>,
			<6148 5468 5159 5058 5027 5021>,
			<6194 5506 5170 5057 5027 5019>,
			<6239 5550 5184 5054 5022 5013>,
			<6284 5600 5202 5051 5018 5010>,
			<6325 5653 5222 5049 5015 5010>,
			<6361 5712 5245 5047 5014 5010>,
			<6394 5775 5270 5049 5015 5012>,
			<6426 5842 5298 5052 5019 5015>,
			<6457 5919 5333 5055 5018 5014>,
			<6497 6011 5374 5056 5012 5009>,
			<6553 6118 5398 5050 5008 5000>,
			<6644 6189 5451 5060 5016 5010>,
			<6674 6286 5512 5068 5025 5022>,
			<6764 6396 5588 5078 5038 5036>,
			<6921 6520 5692 5094 5052 5049>,
			<7201 6688 5840 5109 5052 5045>,
			<8133 7055 6056 5100 5031 5022>,
			<10769 8801 6422 5097 5024 5018>,
			<18261 16402 7289 5123 5031 5022>,
			<46153 62544 13257 5165 5045 5035>,
			<46153 62544 13257 5165 5045 5035>,
			<46153 62544 13257 5165 5045 5035>;
	};

};
